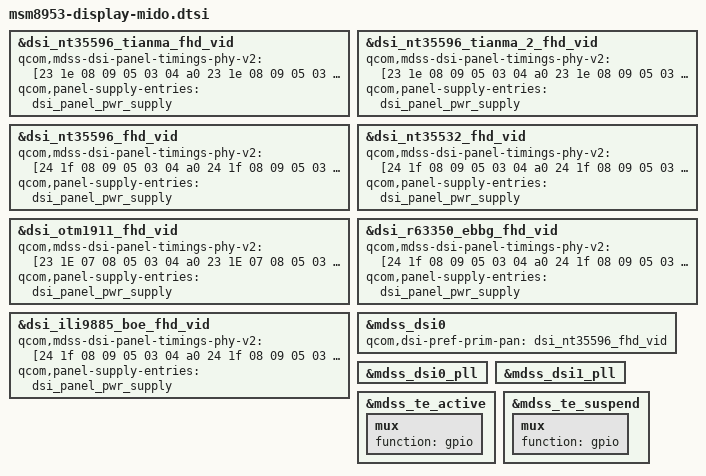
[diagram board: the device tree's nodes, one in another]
#include "dsi-panel-nt35532-fhd-video.dtsi"
#include "dsi-panel-nt35596-fhd-video.dtsi"
#include "dsi-panel-nt35596-tianma-fhd-video.dtsi"
#include "dsi-panel-nt35596-tianma_2-fhd-video.dtsi"
#include "dsi-panel-otm1911-fhd-video.dtsi"
#include "dsi-panel-r63350-ebbg-fhd-video.dtsi"
#include "dsi-panel-ili9885-boe-fhd-video.dtsi"

&dsi_nt35596_tianma_fhd_vid {
	qcom,mdss-dsi-panel-timings-phy-v2 = [23 1e 08 09 05 03 04 a0
	        23 1e 08 09 05 03 04 a0
	        23 1e 08 09 05 03 04 a0
	        23 1e 08 09 05 03 04 a0
	        23 1a 08 09 05 03 04 a0];
	qcom,panel-supply-entries = <&dsi_panel_pwr_supply>;
};

&dsi_nt35596_tianma_2_fhd_vid {
	qcom,mdss-dsi-panel-timings-phy-v2 = [23 1e 08 09 05 03 04 a0
	        23 1e 08 09 05 03 04 a0
	        23 1e 08 09 05 03 04 a0
	        23 1e 08 09 05 03 04 a0
	        23 1a 08 09 05 03 04 a0];
	qcom,panel-supply-entries = <&dsi_panel_pwr_supply>;
};

&dsi_nt35596_fhd_vid {
	qcom,mdss-dsi-panel-timings-phy-v2 = [24 1f 08 09 05 03 04 a0
	        24 1f 08 09 05 03 04 a0
	        24 1f 08 09 05 03 04 a0
	        24 1f 08 09 05 03 04 a0
	        24 1b 08 08 05 03 04 a0];
	qcom,panel-supply-entries = <&dsi_panel_pwr_supply>;
};

&dsi_nt35532_fhd_vid {
	qcom,mdss-dsi-panel-timings-phy-v2 = [24 1f 08 09 05 03 04 a0
	        24 1f 08 09 05 03 04 a0
	        24 1f 08 09 05 03 04 a0
	        24 1f 08 09 05 03 04 a0
	        24 1b 08 09 05 03 04 a0];
	qcom,panel-supply-entries = <&dsi_panel_pwr_supply>;
};

&dsi_otm1911_fhd_vid {
	qcom,mdss-dsi-panel-timings-phy-v2 = [23 1E 07 08 05 03 04 a0
	        23 1E 07 08 05 03 04 a0
	        23 1E 07 08 05 03 04 a0
	        23 1E 07 08 05 03 04 a0
	        23 18 07 08 05 03 04 a0];
	qcom,panel-supply-entries = <&dsi_panel_pwr_supply>;
};

&dsi_r63350_ebbg_fhd_vid {
	qcom,mdss-dsi-panel-timings-phy-v2 = [24 1f 08 09 05 03 04 a0
		24 1f 08 09 05 03 04 a0
		24 1f 08 09 05 03 04 a0
		24 1f 08 09 05 03 04 a0
	        24 1b 08 09 05 03 04 a0];
	qcom,panel-supply-entries = <&dsi_panel_pwr_supply>;
};

&dsi_ili9885_boe_fhd_vid {
	qcom,mdss-dsi-panel-timings-phy-v2 = [24 1f 08 09 05 03 04 a0
		24 1f 08 09 05 03 04 a0
		24 1f 08 09 05 03 04 a0
		24 1f 08 09 05 03 04 a0
	        24 1B 08 09 05 03 04 a0];
	qcom,panel-supply-entries = <&dsi_panel_pwr_supply>;
};

&mdss_dsi0 {
        qcom,dsi-pref-prim-pan = <&dsi_nt35596_fhd_vid>;
};

&mdss_dsi0_pll {
        /delete-property/ qcom,dsi-pll-ssc-en;
        /delete-property/ qcom,dsi-pll-ssc-mode;
};

&mdss_dsi1_pll {
        /delete-property/ qcom,dsi-pll-ssc-en;
        /delete-property/ qcom,dsi-pll-ssc-mode;
};

&mdss_te_active {
        mux {
                function = "gpio";
        };
};

&mdss_te_suspend {
        mux {
                function = "gpio";
        };
};
